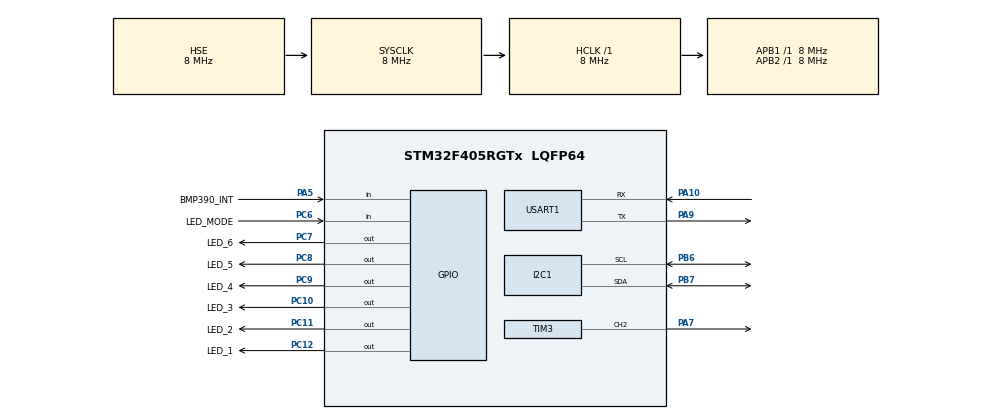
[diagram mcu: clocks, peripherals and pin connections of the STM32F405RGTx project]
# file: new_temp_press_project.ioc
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Dma.Request0=USART1_RX
Dma.Request1=USART1_TX
Dma.USART1_RX.0.Direction=DMA_PERIPH_TO_MEMORY
Dma.USART1_RX.0.FIFOMode=DMA_FIFOMODE_DISABLE
Dma.USART1_RX.0.Instance=DMA2_Stream2
Dma.USART1_RX.0.MemDataAlignment=DMA_MDATAALIGN_BYTE
Dma.USART1_RX.0.MemInc=DMA_MINC_ENABLE
Dma.USART1_RX.0.Mode=DMA_NORMAL
Dma.USART1_RX.0.PeriphDataAlignment=DMA_PDATAALIGN_BYTE
Dma.USART1_RX.0.PeriphInc=DMA_PINC_DISABLE
Dma.USART1_RX.0.Priority=DMA_PRIORITY_VERY_HIGH
Dma.USART1_TX.1.Direction=DMA_MEMORY_TO_PERIPH
Dma.USART1_TX.1.FIFOMode=DMA_FIFOMODE_DISABLE
Dma.USART1_TX.1.Instance=DMA2_Stream7
Dma.USART1_TX.1.MemDataAlignment=DMA_MDATAALIGN_BYTE
Dma.USART1_TX.1.MemInc=DMA_MINC_ENABLE
Dma.USART1_TX.1.Mode=DMA_NORMAL
Dma.USART1_TX.1.PeriphDataAlignment=DMA_PDATAALIGN_BYTE
Dma.USART1_TX.1.PeriphInc=DMA_PINC_DISABLE
Dma.USART1_TX.1.Priority=DMA_PRIORITY_VERY_HIGH
Mcu.Family=STM32F4
Mcu.Name=STM32F405RGTx
Mcu.Package=LQFP64
NVIC.DMA2_Stream2_IRQn=true\:0\:0\:false\:false\:true\:false\:true\:true
NVIC.DMA2_Stream7_IRQn=true\:0\:0\:false\:false\:true\:false\:true\:true
NVIC.PriorityGroup=NVIC_PRIORITYGROUP_4
NVIC.TIM2_IRQn=true\:0\:0\:false\:false\:true\:true\:true\:true
NVIC.USART1_IRQn=true\:0\:0\:false\:false\:true\:true\:true\:true
PA10.Mode=Asynchronous
PA10.Signal=USART1_RX
PA13.Mode=JTAG_4_pins
PA13.Signal=SYS_JTMS-SWDIO
PA14.Mode=JTAG_4_pins
PA14.Signal=SYS_JTCK-SWCLK
PA15.Mode=JTAG_4_pins
PA15.Signal=SYS_JTDI
PA5.GPIO_Label=BMP390_INT
PA5.Signal=GPIO_Input
PA7.Signal=S_TIM3_CH2
PA9.Mode=Asynchronous
PA9.Signal=USART1_TX
PB3.Mode=JTAG_4_pins
PB3.Signal=SYS_JTDO-SWO
PB6.Mode=I2C
PB6.Signal=I2C1_SCL
PB7.Mode=I2C
PB7.Signal=I2C1_SDA
PC10.GPIO_Label=LED_3
PC10.Signal=GPIO_Output
PC11.GPIO_Label=LED_2
PC11.Signal=GPIO_Output
PC12.GPIO_Label=LED_1
PC12.Signal=GPIO_Output
PC6.GPIO_Label=LED_MODE
PC6.Signal=GPIO_Input
PC7.GPIO_Label=LED_6
PC7.Signal=GPIO_Output
PC8.GPIO_Label=LED_5
PC8.Signal=GPIO_Output
PC9.GPIO_Label=LED_4
PC9.Signal=GPIO_Output
PH0-OSC_IN.Mode=HSE-External-Oscillator
PH0-OSC_IN.Signal=RCC_OSC_IN
PH1-OSC_OUT.Mode=HSE-External-Oscillator
PH1-OSC_OUT.Signal=RCC_OSC_OUT
ProjectManager.HeapSize=0x200
ProjectManager.StackSize=0x400
ProjectManager.TargetToolchain=STM32CubeIDE
RCC.AHBFreq_Value=8000000
RCC.APB1Freq_Value=8000000
RCC.APB1TimFreq_Value=8000000
RCC.APB2Freq_Value=8000000
RCC.APB2TimFreq_Value=8000000
RCC.CortexFreq_Value=8000000
RCC.HCLKFreq_Value=8000000
RCC.HSE_VALUE=8000000
RCC.HSI_VALUE=16000000
RCC.LSE_VALUE=32768
RCC.SYSCLKFreq_VALUE=8000000
RCC.SYSCLKSource=RCC_SYSCLKSOURCE_HSE
RCC.VCOOutputFreq_Value=192000000
SH.S_TIM3_CH2.0=TIM3_CH2,PWM Generation2 CH2
TIM2.Period=1000-1
TIM2.Prescaler=8000-1
TIM3.Channel-PWM\ Generation2\ CH2=TIM_CHANNEL_2
TIM3.Period=1000-1
TIM3.Prescaler=8000-1
TIM3.Pulse-PWM\ Generation2\ CH2=500
USART1.VirtualMode=VM_ASYNC
VP_TIM2_VS_ClockSourceINT.Mode=Internal
VP_TIM3_VS_ClockSourceINT.Mode=Internal
board=custom

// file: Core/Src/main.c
/* USER CODE BEGIN Header */
/**
  ******************************************************************************
  * @file           : main.c
  * @brief          : Main program body
  ******************************************************************************
  * @attention
  *
  * Copyright (c) 2025 STMicroelectronics.
  * All rights reserved.
  *
  * This software is licensed under terms that can be found in the LICENSE file
  * in the root directory of this software component.
  * If no LICENSE file comes with this software, it is provided AS-IS.
  *
  ******************************************************************************
  */
/* USER CODE END Header */
#include "main.h"

/* USER CODE BEGIN Includes */
#include <temppress.h>
/* USER CODE END Includes */

I2C_HandleTypeDef hi2c1;

TIM_HandleTypeDef htim2;
TIM_HandleTypeDef htim3;

UART_HandleTypeDef huart1;
DMA_HandleTypeDef hdma_usart1_rx;
DMA_HandleTypeDef hdma_usart1_tx;

void SystemClock_Config(void);
static void MX_GPIO_Init(void);
static void MX_DMA_Init(void);
static void MX_I2C1_Init(void);
static void MX_USART1_UART_Init(void);
static void MX_TIM3_Init(void);
static void MX_TIM2_Init(void);

/* USER CODE BEGIN 0 */
TempPress deviceState;
/* USER CODE END 0 */

int main(void)
{

  /* MCU Configuration--------------------------------------------------------*/

  /* Reset of all peripherals, Initializes the Flash interface and the Systick. */
  HAL_Init();

  /* Configure the system clock */
  SystemClock_Config();

  /* Initialize all configured peripherals */
  MX_GPIO_Init();
  MX_DMA_Init();
  MX_I2C1_Init();
  MX_USART1_UART_Init();
  MX_TIM3_Init();
  MX_TIM2_Init();
  /* USER CODE BEGIN 2 */

  TempPress_Init(&deviceState);

  /* USER CODE END 2 */

  /* Infinite loop */
  /* USER CODE BEGIN WHILE */
  while (1)
  {
	  TempPress_Loop(&deviceState);
    /* USER CODE END WHILE */

  }
}

void SystemClock_Config(void)
{
  RCC_OscInitTypeDef RCC_OscInitStruct = {0};
  RCC_ClkInitTypeDef RCC_ClkInitStruct = {0};

  /** Configure the main internal regulator output voltage
  */
  __HAL_RCC_PWR_CLK_ENABLE();
  __HAL_PWR_VOLTAGESCALING_CONFIG(PWR_REGULATOR_VOLTAGE_SCALE1);

  /** Initializes the RCC Oscillators according to the specified parameters
  * in the RCC_OscInitTypeDef structure.
  */
  RCC_OscInitStruct.OscillatorType = RCC_OSCILLATORTYPE_HSE;
  RCC_OscInitStruct.HSEState = RCC_HSE_ON;
  RCC_OscInitStruct.PLL.PLLState = RCC_PLL_NONE;
  if (HAL_RCC_OscConfig(&RCC_OscInitStruct) != HAL_OK)
  {
    Error_Handler();
  }

  /** Initializes the CPU, AHB and APB buses clocks
  */
  RCC_ClkInitStruct.ClockType = RCC_CLOCKTYPE_HCLK|RCC_CLOCKTYPE_SYSCLK
                              |RCC_CLOCKTYPE_PCLK1|RCC_CLOCKTYPE_PCLK2;
  RCC_ClkInitStruct.SYSCLKSource = RCC_SYSCLKSOURCE_HSE;
  RCC_ClkInitStruct.AHBCLKDivider = RCC_SYSCLK_DIV1;
  RCC_ClkInitStruct.APB1CLKDivider = RCC_HCLK_DIV1;
  RCC_ClkInitStruct.APB2CLKDivider = RCC_HCLK_DIV1;

  if (HAL_RCC_ClockConfig(&RCC_ClkInitStruct, FLASH_LATENCY_0) != HAL_OK)
  {
    Error_Handler();
  }
}

static void MX_I2C1_Init(void)
{

  hi2c1.Instance = I2C1;
  hi2c1.Init.ClockSpeed = 100000;
  hi2c1.Init.DutyCycle = I2C_DUTYCYCLE_2;
  hi2c1.Init.OwnAddress1 = 0;
  hi2c1.Init.AddressingMode = I2C_ADDRESSINGMODE_7BIT;
  hi2c1.Init.DualAddressMode = I2C_DUALADDRESS_DISABLE;
  hi2c1.Init.OwnAddress2 = 0;
  hi2c1.Init.GeneralCallMode = I2C_GENERALCALL_DISABLE;
  hi2c1.Init.NoStretchMode = I2C_NOSTRETCH_DISABLE;
  if (HAL_I2C_Init(&hi2c1) != HAL_OK)
  {
    Error_Handler();
  }

}

static void MX_TIM2_Init(void)
{

  TIM_ClockConfigTypeDef sClockSourceConfig = {0};
  TIM_MasterConfigTypeDef sMasterConfig = {0};

  htim2.Instance = TIM2;
  htim2.Init.Prescaler = 8000-1;
  htim2.Init.CounterMode = TIM_COUNTERMODE_UP;
  htim2.Init.Period = 1000-1;
  htim2.Init.ClockDivision = TIM_CLOCKDIVISION_DIV1;
  htim2.Init.AutoReloadPreload = TIM_AUTORELOAD_PRELOAD_DISABLE;
  if (HAL_TIM_Base_Init(&htim2) != HAL_OK)
  {
    Error_Handler();
  }
  sClockSourceConfig.ClockSource = TIM_CLOCKSOURCE_INTERNAL;
  if (HAL_TIM_ConfigClockSource(&htim2, &sClockSourceConfig) != HAL_OK)
  {
    Error_Handler();
  }
  sMasterConfig.MasterOutputTrigger = TIM_TRGO_RESET;
  sMasterConfig.MasterSlaveMode = TIM_MASTERSLAVEMODE_DISABLE;
  if (HAL_TIMEx_MasterConfigSynchronization(&htim2, &sMasterConfig) != HAL_OK)
  {
    Error_Handler();
  }

}

static void MX_TIM3_Init(void)
{

  TIM_ClockConfigTypeDef sClockSourceConfig = {0};
  TIM_MasterConfigTypeDef sMasterConfig = {0};
  TIM_OC_InitTypeDef sConfigOC = {0};

  htim3.Instance = TIM3;
  htim3.Init.Prescaler = 8000-1;
  htim3.Init.CounterMode = TIM_COUNTERMODE_UP;
  htim3.Init.Period = 1000-1;
  htim3.Init.ClockDivision = TIM_CLOCKDIVISION_DIV1;
  htim3.Init.AutoReloadPreload = TIM_AUTORELOAD_PRELOAD_DISABLE;
  if (HAL_TIM_Base_Init(&htim3) != HAL_OK)
  {
    Error_Handler();
  }
  sClockSourceConfig.ClockSource = TIM_CLOCKSOURCE_INTERNAL;
  if (HAL_TIM_ConfigClockSource(&htim3, &sClockSourceConfig) != HAL_OK)
  {
    Error_Handler();
  }
  if (HAL_TIM_PWM_Init(&htim3) != HAL_OK)
  {
    Error_Handler();
  }
  sMasterConfig.MasterOutputTrigger = TIM_TRGO_RESET;
  sMasterConfig.MasterSlaveMode = TIM_MASTERSLAVEMODE_DISABLE;
  if (HAL_TIMEx_MasterConfigSynchronization(&htim3, &sMasterConfig) != HAL_OK)
  {
    Error_Handler();
  }
  sConfigOC.OCMode = TIM_OCMODE_PWM1;
  sConfigOC.Pulse = 500;
  sConfigOC.OCPolarity = TIM_OCPOLARITY_HIGH;
  sConfigOC.OCFastMode = TIM_OCFAST_DISABLE;
  if (HAL_TIM_PWM_ConfigChannel(&htim3, &sConfigOC, TIM_CHANNEL_2) != HAL_OK)
  {
    Error_Handler();
  }
  HAL_TIM_MspPostInit(&htim3);

}

static void MX_USART1_UART_Init(void)
{

  huart1.Instance = USART1;
  huart1.Init.BaudRate = 115200;
  huart1.Init.WordLength = UART_WORDLENGTH_8B;
  huart1.Init.StopBits = UART_STOPBITS_1;
  huart1.Init.Parity = UART_PARITY_NONE;
  huart1.Init.Mode = UART_MODE_TX_RX;
  huart1.Init.HwFlowCtl = UART_HWCONTROL_NONE;
  huart1.Init.OverSampling = UART_OVERSAMPLING_16;
  if (HAL_UART_Init(&huart1) != HAL_OK)
  {
    Error_Handler();
  }

}

static void MX_DMA_Init(void)
{

  /* DMA controller clock enable */
  __HAL_RCC_DMA2_CLK_ENABLE();

  /* DMA interrupt init */
  /* DMA2_Stream2_IRQn interrupt configuration */
  HAL_NVIC_SetPriority(DMA2_Stream2_IRQn, 0, 0);
  HAL_NVIC_EnableIRQ(DMA2_Stream2_IRQn);
  /* DMA2_Stream7_IRQn interrupt configuration */
  HAL_NVIC_SetPriority(DMA2_Stream7_IRQn, 0, 0);
  HAL_NVIC_EnableIRQ(DMA2_Stream7_IRQn);

}

static void MX_GPIO_Init(void)
{
  GPIO_InitTypeDef GPIO_InitStruct = {0};

  /* GPIO Ports Clock Enable */
  __HAL_RCC_GPIOH_CLK_ENABLE();
  __HAL_RCC_GPIOA_CLK_ENABLE();
  __HAL_RCC_GPIOC_CLK_ENABLE();
  __HAL_RCC_GPIOB_CLK_ENABLE();

  /*Configure GPIO pin Output Level */
  HAL_GPIO_WritePin(GPIOC, LED_6_Pin|LED_5_Pin|LED_4_Pin|LED_3_Pin
                          |LED_2_Pin|LED_1_Pin, GPIO_PIN_RESET);

  /*Configure GPIO pin : BMP390_INT_Pin */
  GPIO_InitStruct.Pin = BMP390_INT_Pin;
  GPIO_InitStruct.Mode = GPIO_MODE_INPUT;
  GPIO_InitStruct.Pull = GPIO_NOPULL;
  HAL_GPIO_Init(BMP390_INT_GPIO_Port, &GPIO_InitStruct);

  /*Configure GPIO pin : LED_MODE_Pin */
  GPIO_InitStruct.Pin = LED_MODE_Pin;
  GPIO_InitStruct.Mode = GPIO_MODE_INPUT;
  GPIO_InitStruct.Pull = GPIO_NOPULL;
  HAL_GPIO_Init(LED_MODE_GPIO_Port, &GPIO_InitStruct);

  /*Configure GPIO pins : LED_6_Pin LED_5_Pin LED_4_Pin LED_3_Pin
                           LED_2_Pin LED_1_Pin */
  GPIO_InitStruct.Pin = LED_6_Pin|LED_5_Pin|LED_4_Pin|LED_3_Pin
                          |LED_2_Pin|LED_1_Pin;
  GPIO_InitStruct.Mode = GPIO_MODE_OUTPUT_PP;
  GPIO_InitStruct.Pull = GPIO_NOPULL;
  GPIO_InitStruct.Speed = GPIO_SPEED_FREQ_LOW;
  HAL_GPIO_Init(GPIOC, &GPIO_InitStruct);

}

void Error_Handler(void)
{
  __disable_irq();
  while (1)
  {
  }
}
